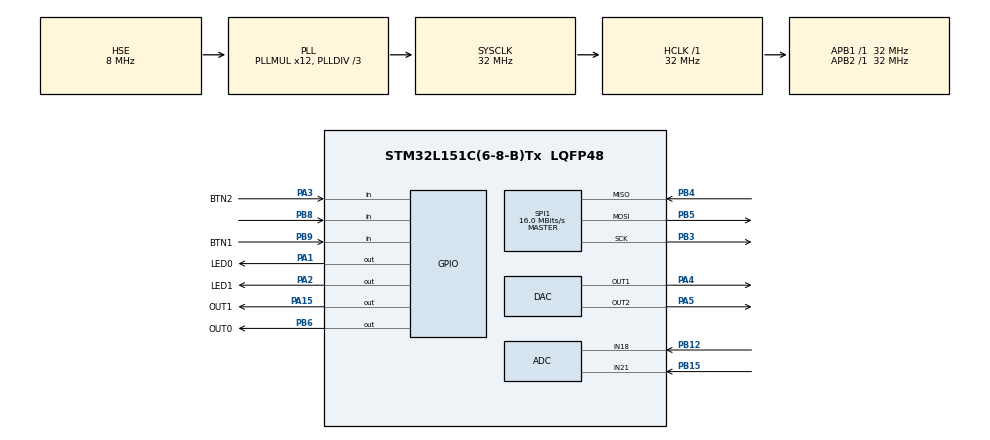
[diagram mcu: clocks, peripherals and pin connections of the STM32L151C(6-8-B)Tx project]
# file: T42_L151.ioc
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ADC.Channel-0\#ChannelRegularConversion=ADC_CHANNEL_21
ADC.Channel-1\#ChannelRegularConversion=ADC_CHANNEL_18
ADC.ClockPrescaler=ADC_CLOCK_ASYNC_DIV1
ADC.ContinuousConvMode=DISABLE
ADC.DMAContinuousRequests=ENABLE
ADC.ExternalTrigConv=ADC_EXTERNALTRIGCONV_T6_TRGO
ADC.NbrOfConversion=2
ADC.NbrOfConversionFlag=1
ADC.Rank-0\#ChannelRegularConversion=1
ADC.Rank-1\#ChannelRegularConversion=2
ADC.SamplingTime-0\#ChannelRegularConversion=ADC_SAMPLETIME_192CYCLES
ADC.SamplingTime-1\#ChannelRegularConversion=ADC_SAMPLETIME_192CYCLES
ADC.ScanConvMode=ADC_SCAN_ENABLE
DAC.DAC_Trigger=DAC_TRIGGER_T2_TRGO
DAC.DAC_Trigger2=DAC_TRIGGER_T2_TRGO
DAC.WaveGeneration=DISABLE
DAC.WaveGeneration2=DISABLE
Dma.ADC.0.Direction=DMA_PERIPH_TO_MEMORY
Dma.ADC.0.Instance=DMA1_Channel1
Dma.ADC.0.MemDataAlignment=DMA_MDATAALIGN_WORD
Dma.ADC.0.MemInc=DMA_MINC_ENABLE
Dma.ADC.0.Mode=DMA_CIRCULAR
Dma.ADC.0.PeriphDataAlignment=DMA_PDATAALIGN_WORD
Dma.ADC.0.PeriphInc=DMA_PINC_DISABLE
Dma.ADC.0.Priority=DMA_PRIORITY_LOW
Dma.DAC_CH1.1.Direction=DMA_MEMORY_TO_PERIPH
Dma.DAC_CH1.1.Instance=DMA1_Channel2
Dma.DAC_CH1.1.MemDataAlignment=DMA_MDATAALIGN_HALFWORD
Dma.DAC_CH1.1.MemInc=DMA_MINC_ENABLE
Dma.DAC_CH1.1.Mode=DMA_CIRCULAR
Dma.DAC_CH1.1.PeriphDataAlignment=DMA_PDATAALIGN_WORD
Dma.DAC_CH1.1.PeriphInc=DMA_PINC_DISABLE
Dma.DAC_CH1.1.Priority=DMA_PRIORITY_MEDIUM
Dma.DAC_CH2.2.Direction=DMA_MEMORY_TO_PERIPH
Dma.DAC_CH2.2.Instance=DMA1_Channel3
Dma.DAC_CH2.2.MemDataAlignment=DMA_MDATAALIGN_HALFWORD
Dma.DAC_CH2.2.MemInc=DMA_MINC_ENABLE
Dma.DAC_CH2.2.Mode=DMA_CIRCULAR
Dma.DAC_CH2.2.PeriphDataAlignment=DMA_PDATAALIGN_WORD
Dma.DAC_CH2.2.PeriphInc=DMA_PINC_DISABLE
Dma.DAC_CH2.2.Priority=DMA_PRIORITY_MEDIUM
Dma.Request0=ADC
Dma.Request1=DAC_CH1
Dma.Request2=DAC_CH2
Mcu.Family=STM32L1
Mcu.Name=STM32L151C(6-8-B)Tx
Mcu.Package=LQFP48
Mcu.UserConstants=TIMESTEP,0.09;BUFSWAPCNT,3;TIM_DAC,htim2;TIM_FRAME,htim6;TIM_GAME,htim7;DAC_OUT,hdac;ADC_POTS,hadc
NVIC.DMA1_Channel2_IRQn=true\:4\:0\:true\:false\:true\:false\:true\:true
NVIC.PriorityGroup=NVIC_PRIORITYGROUP_4
NVIC.TIM6_IRQn=true\:7\:0\:true\:false\:true\:true\:true\:true
NVIC.TIM7_IRQn=true\:11\:0\:true\:false\:true\:true\:true\:true
PA1.GPIO_Label=LED0
PA1.Signal=GPIO_Output
PA13.Mode=Serial_Wire
PA13.Signal=SYS_JTMS-SWDIO
PA14.Mode=Serial_Wire
PA14.Signal=SYS_JTCK-SWCLK
PA15.GPIO_Label=OUT1
PA15.Signal=GPIO_Output
PA2.GPIO_Label=LED1
PA2.Signal=GPIO_Output
PA3.GPIO_Label=BTN2
PA3.Signal=GPIO_Input
PA4.Signal=COMP_DAC1_group
PA5.Signal=COMP_DAC2_group
PB12.Mode=IN18
PB12.Signal=ADC_IN18
PB15.Mode=IN21
PB15.Signal=ADC_IN21
PB3.Mode=Full_Duplex_Master
PB3.Signal=SPI1_SCK
PB4.Mode=Full_Duplex_Master
PB4.Signal=SPI1_MISO
PB5.Mode=Full_Duplex_Master
PB5.Signal=SPI1_MOSI
PB6.GPIO_Label=OUT0
PB6.Signal=GPIO_Output
PB8.Signal=GPIO_Input
PB9.GPIO_Label=BTN1
PB9.Signal=GPIO_Input
PH0-OSC_IN.Mode=HSE-External-Oscillator
PH0-OSC_IN.Signal=RCC_OSC_IN
PH1-OSC_OUT.Mode=HSE-External-Oscillator
PH1-OSC_OUT.Signal=RCC_OSC_OUT
ProjectManager.HeapSize=0x200
ProjectManager.StackSize=0x400
ProjectManager.TargetToolchain=STM32CubeIDE
RCC.48MHZClocksFreq_Value=48000000
RCC.AHBFreq_Value=32000000
RCC.APB1Freq_Value=32000000
RCC.APB1TimFreq_Value=32000000
RCC.APB2Freq_Value=32000000
RCC.APB2TimFreq_Value=32000000
RCC.HCLKFreq_Value=32000000
RCC.HSE_VALUE=8000000
RCC.HSI_VALUE=16000000
RCC.LSE_VALUE=32768
RCC.MSI_VALUE=2097000
RCC.PLLDIV=RCC_PLL_DIV3
RCC.PLLMUL=RCC_PLL_MUL12
RCC.PLLSourceVirtual=RCC_PLLSOURCE_HSE
RCC.SYSCLKFreq_VALUE=32000000
RCC.SYSCLKSource=RCC_SYSCLKSOURCE_PLLCLK
RCC.VCOOutputFreq_Value=96000000
SH.COMP_DAC1_group.0=DAC_OUT1,DAC_OUT1
SH.COMP_DAC2_group.0=DAC_OUT2,DAC_OUT2
SPI1.CalculateBaudRate=16.0 MBits/s
SPI1.Direction=SPI_DIRECTION_2LINES
SPI1.Mode=SPI_MODE_MASTER
SPI1.VirtualType=VM_MASTER
TIM2.Period=64
TIM2.TIM_MasterOutputTrigger=TIM_TRGO_UPDATE
TIM4.Period=4096
TIM6.AutoReloadPreload=TIM_AUTORELOAD_PRELOAD_DISABLE
TIM6.Period=400
TIM6.Prescaler=319
TIM6.TIM_MasterOutputTrigger=TIM_TRGO_UPDATE
TIM7.Period=400
TIM7.Prescaler=319
VP_TIM2_VS_ClockSourceINT.Mode=Internal
VP_TIM4_VS_ClockSourceITR.Mode=TriggerSource_ITR0
VP_TIM4_VS_ControllerModeTrigger.Mode=Trigger Mode
VP_TIM6_VS_ClockSourceINT.Mode=Enable_Timer
VP_TIM7_VS_ClockSourceINT.Mode=Enable_Timer
board=custom

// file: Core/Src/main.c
/* USER CODE BEGIN Header */
/**
  ******************************************************************************
  * @file           : main.c
  * @brief          : Main program body
  ******************************************************************************
  * @attention
  *
  * Copyright (c) 2025 STMicroelectronics.
  * All rights reserved.
  *
  * This software is licensed under terms that can be found in the LICENSE file
  * in the root directory of this software component.
  * If no LICENSE file comes with this software, it is provided AS-IS.
  *
  ******************************************************************************
  */
/* USER CODE END Header */
#include "main.h"

/* USER CODE BEGIN Includes */
#include "t42.h"
/* USER CODE END Includes */

ADC_HandleTypeDef hadc;
DMA_HandleTypeDef hdma_adc;

DAC_HandleTypeDef hdac;
DMA_HandleTypeDef hdma_dac_ch1;
DMA_HandleTypeDef hdma_dac_ch2;

SPI_HandleTypeDef hspi1;

TIM_HandleTypeDef htim2;
TIM_HandleTypeDef htim4;
TIM_HandleTypeDef htim6;
TIM_HandleTypeDef htim7;

void SystemClock_Config(void);
static void MX_GPIO_Init(void);
static void MX_DMA_Init(void);
static void MX_ADC_Init(void);
static void MX_DAC_Init(void);
static void MX_SPI1_Init(void);
static void MX_TIM6_Init(void);
static void MX_TIM2_Init(void);
static void MX_TIM4_Init(void);
static void MX_TIM7_Init(void);

int main(void)
{

  /* MCU Configuration--------------------------------------------------------*/

  /* Reset of all peripherals, Initializes the Flash interface and the Systick. */
  HAL_Init();

  /* Configure the system clock */
  SystemClock_Config();

  /* Initialize all configured peripherals */
  MX_GPIO_Init();
  MX_DMA_Init();
  MX_ADC_Init();
  MX_DAC_Init();
  MX_SPI1_Init();
  MX_TIM6_Init();
  MX_TIM2_Init();
  MX_TIM4_Init();
  MX_TIM7_Init();
  /* USER CODE BEGIN 2 */
  HAL_GPIO_WritePin(LED0_GPIO_Port, LED0_Pin, 1);
  HAL_GPIO_WritePin(LED1_GPIO_Port, LED1_Pin, 1);
  HAL_Delay(200);
  HAL_GPIO_WritePin(LED0_GPIO_Port, LED0_Pin, 0);
  HAL_GPIO_WritePin(LED1_GPIO_Port, LED1_Pin, 0);

  setupGame();

  /* USER CODE END 2 */

  /* Infinite loop */
  /* USER CODE BEGIN WHILE */
  while (1)
  {
	  updateGame();
    /* USER CODE END WHILE */

  }
}

void SystemClock_Config(void)
{
  RCC_OscInitTypeDef RCC_OscInitStruct = {0};
  RCC_ClkInitTypeDef RCC_ClkInitStruct = {0};

  /** Configure the main internal regulator output voltage
  */
  __HAL_PWR_VOLTAGESCALING_CONFIG(PWR_REGULATOR_VOLTAGE_SCALE1);

  /** Initializes the RCC Oscillators according to the specified parameters
  * in the RCC_OscInitTypeDef structure.
  */
  RCC_OscInitStruct.OscillatorType = RCC_OSCILLATORTYPE_HSI|RCC_OSCILLATORTYPE_HSE;
  RCC_OscInitStruct.HSEState = RCC_HSE_ON;
  RCC_OscInitStruct.HSIState = RCC_HSI_ON;
  RCC_OscInitStruct.HSICalibrationValue = RCC_HSICALIBRATION_DEFAULT;
  RCC_OscInitStruct.PLL.PLLState = RCC_PLL_ON;
  RCC_OscInitStruct.PLL.PLLSource = RCC_PLLSOURCE_HSE;
  RCC_OscInitStruct.PLL.PLLMUL = RCC_PLL_MUL12;
  RCC_OscInitStruct.PLL.PLLDIV = RCC_PLL_DIV3;
  if (HAL_RCC_OscConfig(&RCC_OscInitStruct) != HAL_OK)
  {
    Error_Handler();
  }

  /** Initializes the CPU, AHB and APB buses clocks
  */
  RCC_ClkInitStruct.ClockType = RCC_CLOCKTYPE_HCLK|RCC_CLOCKTYPE_SYSCLK
                              |RCC_CLOCKTYPE_PCLK1|RCC_CLOCKTYPE_PCLK2;
  RCC_ClkInitStruct.SYSCLKSource = RCC_SYSCLKSOURCE_PLLCLK;
  RCC_ClkInitStruct.AHBCLKDivider = RCC_SYSCLK_DIV1;
  RCC_ClkInitStruct.APB1CLKDivider = RCC_HCLK_DIV1;
  RCC_ClkInitStruct.APB2CLKDivider = RCC_HCLK_DIV1;

  if (HAL_RCC_ClockConfig(&RCC_ClkInitStruct, FLASH_LATENCY_1) != HAL_OK)
  {
    Error_Handler();
  }
}

static void MX_ADC_Init(void)
{

  ADC_ChannelConfTypeDef sConfig = {0};

  /** Configure the global features of the ADC (Clock, Resolution, Data Alignment and number of conversion)
  */
  hadc.Instance = ADC1;
  hadc.Init.ClockPrescaler = ADC_CLOCK_ASYNC_DIV1;
  hadc.Init.Resolution = ADC_RESOLUTION_12B;
  hadc.Init.DataAlign = ADC_DATAALIGN_RIGHT;
  hadc.Init.ScanConvMode = ADC_SCAN_ENABLE;
  hadc.Init.EOCSelection = ADC_EOC_SEQ_CONV;
  hadc.Init.LowPowerAutoWait = ADC_AUTOWAIT_DISABLE;
  hadc.Init.LowPowerAutoPowerOff = ADC_AUTOPOWEROFF_DISABLE;
  hadc.Init.ChannelsBank = ADC_CHANNELS_BANK_A;
  hadc.Init.ContinuousConvMode = DISABLE;
  hadc.Init.NbrOfConversion = 2;
  hadc.Init.DiscontinuousConvMode = DISABLE;
  hadc.Init.ExternalTrigConv = ADC_EXTERNALTRIGCONV_T6_TRGO;
  hadc.Init.ExternalTrigConvEdge = ADC_EXTERNALTRIGCONVEDGE_RISING;
  hadc.Init.DMAContinuousRequests = ENABLE;
  if (HAL_ADC_Init(&hadc) != HAL_OK)
  {
    Error_Handler();
  }

  /** Configure for the selected ADC regular channel its corresponding rank in the sequencer and its sample time.
  */
  sConfig.Channel = ADC_CHANNEL_21;
  sConfig.Rank = ADC_REGULAR_RANK_1;
  sConfig.SamplingTime = ADC_SAMPLETIME_192CYCLES;
  if (HAL_ADC_ConfigChannel(&hadc, &sConfig) != HAL_OK)
  {
    Error_Handler();
  }

  /** Configure for the selected ADC regular channel its corresponding rank in the sequencer and its sample time.
  */
  sConfig.Channel = ADC_CHANNEL_18;
  sConfig.Rank = ADC_REGULAR_RANK_2;
  if (HAL_ADC_ConfigChannel(&hadc, &sConfig) != HAL_OK)
  {
    Error_Handler();
  }

}

static void MX_DAC_Init(void)
{

  DAC_ChannelConfTypeDef sConfig = {0};

  /** DAC Initialization
  */
  hdac.Instance = DAC;
  if (HAL_DAC_Init(&hdac) != HAL_OK)
  {
    Error_Handler();
  }

  /** DAC channel OUT1 config
  */
  sConfig.DAC_Trigger = DAC_TRIGGER_T2_TRGO;
  sConfig.DAC_OutputBuffer = DAC_OUTPUTBUFFER_ENABLE;
  if (HAL_DAC_ConfigChannel(&hdac, &sConfig, DAC_CHANNEL_1) != HAL_OK)
  {
    Error_Handler();
  }

  /** DAC channel OUT2 config
  */
  if (HAL_DAC_ConfigChannel(&hdac, &sConfig, DAC_CHANNEL_2) != HAL_OK)
  {
    Error_Handler();
  }

}

static void MX_SPI1_Init(void)
{

  /* SPI1 parameter configuration*/
  hspi1.Instance = SPI1;
  hspi1.Init.Mode = SPI_MODE_MASTER;
  hspi1.Init.Direction = SPI_DIRECTION_2LINES;
  hspi1.Init.DataSize = SPI_DATASIZE_8BIT;
  hspi1.Init.CLKPolarity = SPI_POLARITY_LOW;
  hspi1.Init.CLKPhase = SPI_PHASE_1EDGE;
  hspi1.Init.NSS = SPI_NSS_SOFT;
  hspi1.Init.BaudRatePrescaler = SPI_BAUDRATEPRESCALER_2;
  hspi1.Init.FirstBit = SPI_FIRSTBIT_MSB;
  hspi1.Init.CRCCalculation = SPI_CRCCALCULATION_DISABLE;
  hspi1.Init.CRCPolynomial = 10;
  if (HAL_SPI_Init(&hspi1) != HAL_OK)
  {
    Error_Handler();
  }

}

static void MX_TIM2_Init(void)
{

  TIM_ClockConfigTypeDef sClockSourceConfig = {0};
  TIM_MasterConfigTypeDef sMasterConfig = {0};

  htim2.Instance = TIM2;
  htim2.Init.Prescaler = 0;
  htim2.Init.CounterMode = TIM_COUNTERMODE_UP;
  htim2.Init.Period = 64;
  htim2.Init.ClockDivision = TIM_CLOCKDIVISION_DIV1;
  htim2.Init.AutoReloadPreload = TIM_AUTORELOAD_PRELOAD_DISABLE;
  if (HAL_TIM_Base_Init(&htim2) != HAL_OK)
  {
    Error_Handler();
  }
  sClockSourceConfig.ClockSource = TIM_CLOCKSOURCE_INTERNAL;
  if (HAL_TIM_ConfigClockSource(&htim2, &sClockSourceConfig) != HAL_OK)
  {
    Error_Handler();
  }
  sMasterConfig.MasterOutputTrigger = TIM_TRGO_UPDATE;
  sMasterConfig.MasterSlaveMode = TIM_MASTERSLAVEMODE_DISABLE;
  if (HAL_TIMEx_MasterConfigSynchronization(&htim2, &sMasterConfig) != HAL_OK)
  {
    Error_Handler();
  }

}

static void MX_TIM4_Init(void)
{

  TIM_SlaveConfigTypeDef sSlaveConfig = {0};
  TIM_MasterConfigTypeDef sMasterConfig = {0};

  htim4.Instance = TIM4;
  htim4.Init.Prescaler = 0;
  htim4.Init.CounterMode = TIM_COUNTERMODE_UP;
  htim4.Init.Period = 4096;
  htim4.Init.ClockDivision = TIM_CLOCKDIVISION_DIV1;
  htim4.Init.AutoReloadPreload = TIM_AUTORELOAD_PRELOAD_DISABLE;
  if (HAL_TIM_Base_Init(&htim4) != HAL_OK)
  {
    Error_Handler();
  }
  sSlaveConfig.SlaveMode = TIM_SLAVEMODE_TRIGGER;
  sSlaveConfig.InputTrigger = TIM_TS_ITR0;
  if (HAL_TIM_SlaveConfigSynchro(&htim4, &sSlaveConfig) != HAL_OK)
  {
    Error_Handler();
  }
  sMasterConfig.MasterOutputTrigger = TIM_TRGO_RESET;
  sMasterConfig.MasterSlaveMode = TIM_MASTERSLAVEMODE_DISABLE;
  if (HAL_TIMEx_MasterConfigSynchronization(&htim4, &sMasterConfig) != HAL_OK)
  {
    Error_Handler();
  }

}

static void MX_TIM6_Init(void)
{

  TIM_MasterConfigTypeDef sMasterConfig = {0};

  htim6.Instance = TIM6;
  htim6.Init.Prescaler = 319;
  htim6.Init.CounterMode = TIM_COUNTERMODE_UP;
  htim6.Init.Period = 400;
  htim6.Init.AutoReloadPreload = TIM_AUTORELOAD_PRELOAD_DISABLE;
  if (HAL_TIM_Base_Init(&htim6) != HAL_OK)
  {
    Error_Handler();
  }
  sMasterConfig.MasterOutputTrigger = TIM_TRGO_UPDATE;
  sMasterConfig.MasterSlaveMode = TIM_MASTERSLAVEMODE_DISABLE;
  if (HAL_TIMEx_MasterConfigSynchronization(&htim6, &sMasterConfig) != HAL_OK)
  {
    Error_Handler();
  }

}

static void MX_TIM7_Init(void)
{

  TIM_MasterConfigTypeDef sMasterConfig = {0};

  htim7.Instance = TIM7;
  htim7.Init.Prescaler = 319;
  htim7.Init.CounterMode = TIM_COUNTERMODE_UP;
  htim7.Init.Period = 400;
  htim7.Init.AutoReloadPreload = TIM_AUTORELOAD_PRELOAD_DISABLE;
  if (HAL_TIM_Base_Init(&htim7) != HAL_OK)
  {
    Error_Handler();
  }
  sMasterConfig.MasterOutputTrigger = TIM_TRGO_RESET;
  sMasterConfig.MasterSlaveMode = TIM_MASTERSLAVEMODE_DISABLE;
  if (HAL_TIMEx_MasterConfigSynchronization(&htim7, &sMasterConfig) != HAL_OK)
  {
    Error_Handler();
  }

}

static void MX_DMA_Init(void)
{

  /* DMA controller clock enable */
  __HAL_RCC_DMA1_CLK_ENABLE();

  /* DMA interrupt init */
  /* DMA1_Channel2_IRQn interrupt configuration */
  HAL_NVIC_SetPriority(DMA1_Channel2_IRQn, 4, 0);
  HAL_NVIC_EnableIRQ(DMA1_Channel2_IRQn);

}

static void MX_GPIO_Init(void)
{
  GPIO_InitTypeDef GPIO_InitStruct = {0};

  /* GPIO Ports Clock Enable */
  __HAL_RCC_GPIOH_CLK_ENABLE();
  __HAL_RCC_GPIOA_CLK_ENABLE();
  __HAL_RCC_GPIOB_CLK_ENABLE();

  /*Configure GPIO pin Output Level */
  HAL_GPIO_WritePin(GPIOA, LED0_Pin|LED1_Pin|OUT1_Pin, GPIO_PIN_RESET);

  /*Configure GPIO pin Output Level */
  HAL_GPIO_WritePin(OUT0_GPIO_Port, OUT0_Pin, GPIO_PIN_RESET);

  /*Configure GPIO pins : LED0_Pin LED1_Pin OUT1_Pin */
  GPIO_InitStruct.Pin = LED0_Pin|LED1_Pin|OUT1_Pin;
  GPIO_InitStruct.Mode = GPIO_MODE_OUTPUT_PP;
  GPIO_InitStruct.Pull = GPIO_NOPULL;
  GPIO_InitStruct.Speed = GPIO_SPEED_FREQ_LOW;
  HAL_GPIO_Init(GPIOA, &GPIO_InitStruct);

  /*Configure GPIO pin : BTN2_Pin */
  GPIO_InitStruct.Pin = BTN2_Pin;
  GPIO_InitStruct.Mode = GPIO_MODE_INPUT;
  GPIO_InitStruct.Pull = GPIO_NOPULL;
  HAL_GPIO_Init(BTN2_GPIO_Port, &GPIO_InitStruct);

  /*Configure GPIO pin : OUT0_Pin */
  GPIO_InitStruct.Pin = OUT0_Pin;
  GPIO_InitStruct.Mode = GPIO_MODE_OUTPUT_PP;
  GPIO_InitStruct.Pull = GPIO_NOPULL;
  GPIO_InitStruct.Speed = GPIO_SPEED_FREQ_LOW;
  HAL_GPIO_Init(OUT0_GPIO_Port, &GPIO_InitStruct);

  /*Configure GPIO pins : PB8 BTN1_Pin */
  GPIO_InitStruct.Pin = GPIO_PIN_8|BTN1_Pin;
  GPIO_InitStruct.Mode = GPIO_MODE_INPUT;
  GPIO_InitStruct.Pull = GPIO_NOPULL;
  HAL_GPIO_Init(GPIOB, &GPIO_InitStruct);

}

void Error_Handler(void)
{
  __disable_irq();
  while (1)
  {
  }
}
